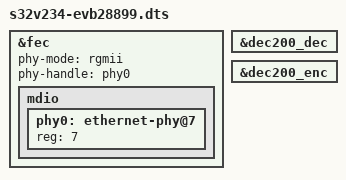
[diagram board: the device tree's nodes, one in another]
/*
 * Copyright 2015 Freescale Semiconductor, Inc.
 * Copyright 2017 NXP
 *
 * This program is free software; you can redistribute it and/or modify
 * it under the terms of the GNU General Public License as published by
 * the Free Software Foundation; either version 2 of the License, or
 * (at your option) any later version.
 */

/dts-v1/;
#include "s32v234-evb28899.dtsi"

&fec {
	phy-mode = "rgmii";
	phy-handle = <&phy0>;
	status = "okay";
	mdio {
		#address-cells = <1>;
		#size-cells = <0>;
		phy0: ethernet-phy@7 {
			reg = <7>;
		};
	};
};

&dec200_dec {
	status = "okay";
};

&dec200_enc {
	status = "okay";
};
